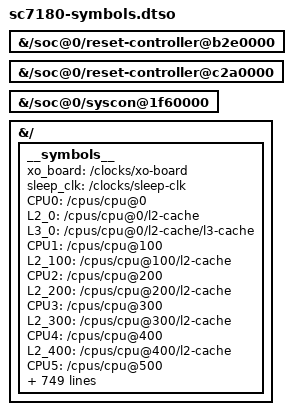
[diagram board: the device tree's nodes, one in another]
// SPDX-License-Identifier: BSD-3-Clause

/dts-v1/;
/plugin/;

/* need to insert a fun phandle to these since base dt doesn't have it... */
&{/soc@0/reset-controller@b2e0000} { phandle = <0x1001>; };
&{/soc@0/reset-controller@c2a0000} { phandle = <0x1002>; };
&{/soc@0/syscon@1f60000} { phandle = <0x1003>; };

/*
 * This is a funny hack to allow phandles on top of a dtb without --symbols
 */
&{/} {
	__symbols__ {
		xo_board = "/clocks/xo-board";
		sleep_clk = "/clocks/sleep-clk";
		CPU0 = "/cpus/cpu@0";
		L2_0 = "/cpus/cpu@0/l2-cache";
		L3_0 = "/cpus/cpu@0/l2-cache/l3-cache";
		CPU1 = "/cpus/cpu@100";
		L2_100 = "/cpus/cpu@100/l2-cache";
		CPU2 = "/cpus/cpu@200";
		L2_200 = "/cpus/cpu@200/l2-cache";
		CPU3 = "/cpus/cpu@300";
		L2_300 = "/cpus/cpu@300/l2-cache";
		CPU4 = "/cpus/cpu@400";
		L2_400 = "/cpus/cpu@400/l2-cache";
		CPU5 = "/cpus/cpu@500";
		L2_500 = "/cpus/cpu@500/l2-cache";
		CPU6 = "/cpus/cpu@600";
		L2_600 = "/cpus/cpu@600/l2-cache";
		CPU7 = "/cpus/cpu@700";
		L2_700 = "/cpus/cpu@700/l2-cache";
		idle_states = "/cpus/idle-states";
		LITTLE_CPU_SLEEP_0 = "/cpus/idle-states/cpu-sleep-0-0";
		LITTLE_CPU_SLEEP_1 = "/cpus/idle-states/cpu-sleep-0-1";
		BIG_CPU_SLEEP_0 = "/cpus/idle-states/cpu-sleep-1-0";
		BIG_CPU_SLEEP_1 = "/cpus/idle-states/cpu-sleep-1-1";
		CLUSTER_SLEEP_0 = "/cpus/idle-states/cluster-sleep-0";
		scm = "/firmware/scm";
		cpu0_opp_table = "/opp-table-cpu0";
		cpu0_opp1 = "/opp-table-cpu0/opp-300000000";
		cpu0_opp2 = "/opp-table-cpu0/opp-576000000";
		cpu0_opp3 = "/opp-table-cpu0/opp-768000000";
		cpu0_opp4 = "/opp-table-cpu0/opp-1017600000";
		cpu0_opp5 = "/opp-table-cpu0/opp-1248000000";
		cpu0_opp6 = "/opp-table-cpu0/opp-1324800000";
		cpu0_opp7 = "/opp-table-cpu0/opp-1516800000";
		cpu0_opp8 = "/opp-table-cpu0/opp-1612800000";
		cpu0_opp9 = "/opp-table-cpu0/opp-1708800000";
		cpu0_opp10 = "/opp-table-cpu0/opp-1804800000";
		cpu6_opp_table = "/opp-table-cpu6";
		cpu6_opp1 = "/opp-table-cpu6/opp-300000000";
		cpu6_opp2 = "/opp-table-cpu6/opp-652800000";
		cpu6_opp3 = "/opp-table-cpu6/opp-825600000";
		cpu6_opp4 = "/opp-table-cpu6/opp-979200000";
		cpu6_opp5 = "/opp-table-cpu6/opp-1113600000";
		cpu6_opp6 = "/opp-table-cpu6/opp-1267200000";
		cpu6_opp7 = "/opp-table-cpu6/opp-1555200000";
		cpu6_opp8 = "/opp-table-cpu6/opp-1708800000";
		cpu6_opp9 = "/opp-table-cpu6/opp-1843200000";
		cpu6_opp10 = "/opp-table-cpu6/opp-1900800000";
		cpu6_opp11 = "/opp-table-cpu6/opp-1996800000";
		cpu6_opp12 = "/opp-table-cpu6/opp-2112000000";
		cpu6_opp13 = "/opp-table-cpu6/opp-2208000000";
		cpu6_opp14 = "/opp-table-cpu6/opp-2323200000";
		cpu6_opp15 = "/opp-table-cpu6/opp-2400000000";
		cpu6_opp16 = "/opp-table-cpu6/opp-2553600000";
		qspi_opp_table = "/opp-table-qspi";
		qup_opp_table = "/opp-table-qup";
		reserved_memory = "/reserved-memory";
		aop_cmd_db_mem = "/reserved-memory/memory@80820000";
		smem_mem = "/reserved-memory/memory@80900000";
		atf_mem = "/reserved-memory/memory@80b00000";
		ipa_fw_mem = "/reserved-memory/memory@8b700000";
		rmtfs_mem = "/reserved-memory/memory@94600000";
		mpss_mem = "/reserved-memory/memory@86000000";
		camera_mem = "/reserved-memory/memory@8ec00000";
		venus_mem = "/reserved-memory/memory@8f600000";
		wlan_mem = "/reserved-memory/memory@94100000";
		mba_mem = "/reserved-memory/memory@94400000";
		mdata_mem = "/reserved-memory/mpss-metadata";
		cdsp_smp2p_out = "/smp2p-cdsp/master-kernel";
		cdsp_smp2p_in = "/smp2p-cdsp/slave-kernel";
		adsp_smp2p_out = "/smp2p-lpass/master-kernel";
		adsp_smp2p_in = "/smp2p-lpass/slave-kernel";
		modem_smp2p_out = "/smp2p-mpss/master-kernel";
		modem_smp2p_in = "/smp2p-mpss/slave-kernel";
		ipa_smp2p_out = "/smp2p-mpss/ipa-ap-to-modem";
		ipa_smp2p_in = "/smp2p-mpss/ipa-modem-to-ap";
		soc = "/soc@0";
		gcc = "/soc@0/clock-controller@100000";
		qfprom = "/soc@0/efuse@784000";
		qusb2p_hstx_trim = "/soc@0/efuse@784000/hstx-trim-primary@25b";
		gpu_speed_bin = "/soc@0/efuse@784000/gpu_speed_bin@1d2";
		sdhc_1 = "/soc@0/mmc@7c4000";
		sdhc1_opp_table = "/soc@0/mmc@7c4000/opp-table";
		qupv3_id_0 = "/soc@0/geniqup@8c0000";
		i2c0 = "/soc@0/geniqup@8c0000/i2c@880000";
		spi0 = "/soc@0/geniqup@8c0000/spi@880000";
		uart0 = "/soc@0/geniqup@8c0000/serial@880000";
		i2c1 = "/soc@0/geniqup@8c0000/i2c@884000";
		spi1 = "/soc@0/geniqup@8c0000/spi@884000";
		uart1 = "/soc@0/geniqup@8c0000/serial@884000";
		i2c2 = "/soc@0/geniqup@8c0000/i2c@888000";
		uart2 = "/soc@0/geniqup@8c0000/serial@888000";
		i2c3 = "/soc@0/geniqup@8c0000/i2c@88c000";
		spi3 = "/soc@0/geniqup@8c0000/spi@88c000";
		uart3 = "/soc@0/geniqup@8c0000/serial@88c000";
		bluetooth = "/soc@0/geniqup@8c0000/serial@88c000/bluetooth";
		i2c4 = "/soc@0/geniqup@8c0000/i2c@890000";
		uart4 = "/soc@0/geniqup@8c0000/serial@890000";
		i2c5 = "/soc@0/geniqup@8c0000/i2c@894000";
		spi5 = "/soc@0/geniqup@8c0000/spi@894000";
		uart5 = "/soc@0/geniqup@8c0000/serial@894000";
		qupv3_id_1 = "/soc@0/geniqup@ac0000";
		i2c6 = "/soc@0/geniqup@ac0000/i2c@a80000";
		spi6 = "/soc@0/geniqup@ac0000/spi@a80000";
		uart6 = "/soc@0/geniqup@ac0000/serial@a80000";
		i2c7 = "/soc@0/geniqup@ac0000/i2c@a84000";
		uart7 = "/soc@0/geniqup@ac0000/serial@a84000";
		i2c8 = "/soc@0/geniqup@ac0000/i2c@a88000";
		spi8 = "/soc@0/geniqup@ac0000/spi@a88000";
		uart8 = "/soc@0/geniqup@ac0000/serial@a88000";
		i2c9 = "/soc@0/geniqup@ac0000/i2c@a8c000";
		uart9 = "/soc@0/geniqup@ac0000/serial@a8c000";
		i2c10 = "/soc@0/geniqup@ac0000/i2c@a90000";
		spi10 = "/soc@0/geniqup@ac0000/spi@a90000";
		uart10 = "/soc@0/geniqup@ac0000/serial@a90000";
		i2c11 = "/soc@0/geniqup@ac0000/i2c@a94000";
		spi11 = "/soc@0/geniqup@ac0000/spi@a94000";
		uart11 = "/soc@0/geniqup@ac0000/serial@a94000";
		config_noc = "/soc@0/interconnect@1500000";
		system_noc = "/soc@0/interconnect@1620000";
		mc_virt = "/soc@0/interconnect@1638000";
		qup_virt = "/soc@0/interconnect@1650000";
		aggre1_noc = "/soc@0/interconnect@16e0000";
		aggre2_noc = "/soc@0/interconnect@1705000";
		compute_noc = "/soc@0/interconnect@170e000";
		mmss_noc = "/soc@0/interconnect@1740000";
		ipa = "/soc@0/ipa@1e40000";
		tcsr_mutex = "/soc@0/hwlock@1f40000";
		tcsr_regs_1 = "/soc@0/syscon@1f60000";
		tcsr_regs_2 = "/soc@0/syscon@1fc0000";
		tlmm = "/soc@0/pinctrl@3500000";
		dp_hot_plug_det = "/soc@0/pinctrl@3500000/dp-hot-plug-det-state";
		qspi_clk = "/soc@0/pinctrl@3500000/qspi-clk-state";
		qspi_cs0 = "/soc@0/pinctrl@3500000/qspi-cs0-state";
		qspi_cs1 = "/soc@0/pinctrl@3500000/qspi-cs1-state";
		qspi_data0 = "/soc@0/pinctrl@3500000/qspi-data0-state";
		qspi_data1 = "/soc@0/pinctrl@3500000/qspi-data1-state";
		qspi_data23 = "/soc@0/pinctrl@3500000/qspi-data23-state";
		qup_i2c0_default = "/soc@0/pinctrl@3500000/qup-i2c0-default-state";
		qup_i2c1_default = "/soc@0/pinctrl@3500000/qup-i2c1-default-state";
		qup_i2c2_default = "/soc@0/pinctrl@3500000/qup-i2c2-default-state";
		qup_i2c3_default = "/soc@0/pinctrl@3500000/qup-i2c3-default-state";
		qup_i2c4_default = "/soc@0/pinctrl@3500000/qup-i2c4-default-state";
		qup_i2c5_default = "/soc@0/pinctrl@3500000/qup-i2c5-default-state";
		qup_i2c6_default = "/soc@0/pinctrl@3500000/qup-i2c6-default-state";
		qup_i2c7_default = "/soc@0/pinctrl@3500000/qup-i2c7-default-state";
		qup_i2c8_default = "/soc@0/pinctrl@3500000/qup-i2c8-default-state";
		qup_i2c9_default = "/soc@0/pinctrl@3500000/qup-i2c9-default-state";
		qup_i2c10_default = "/soc@0/pinctrl@3500000/qup-i2c10-default-state";
		qup_i2c11_default = "/soc@0/pinctrl@3500000/qup-i2c11-default-state";
		qup_spi0_spi = "/soc@0/pinctrl@3500000/qup-spi0-spi-state";
		qup_spi0_cs = "/soc@0/pinctrl@3500000/qup-spi0-cs-state";
		qup_spi0_cs_gpio = "/soc@0/pinctrl@3500000/qup-spi0-cs-gpio-state";
		qup_spi1_spi = "/soc@0/pinctrl@3500000/qup-spi1-spi-state";
		qup_spi1_cs = "/soc@0/pinctrl@3500000/qup-spi1-cs-state";
		qup_spi1_cs_gpio = "/soc@0/pinctrl@3500000/qup-spi1-cs-gpio-state";
		qup_spi3_spi = "/soc@0/pinctrl@3500000/qup-spi3-spi-state";
		qup_spi3_cs = "/soc@0/pinctrl@3500000/qup-spi3-cs-state";
		qup_spi3_cs_gpio = "/soc@0/pinctrl@3500000/qup-spi3-cs-gpio-state";
		qup_spi5_spi = "/soc@0/pinctrl@3500000/qup-spi5-spi-state";
		qup_spi5_cs = "/soc@0/pinctrl@3500000/qup-spi5-cs-state";
		qup_spi5_cs_gpio = "/soc@0/pinctrl@3500000/qup-spi5-cs-gpio-state";
		qup_spi6_spi = "/soc@0/pinctrl@3500000/qup-spi6-spi-state";
		qup_spi6_cs = "/soc@0/pinctrl@3500000/qup-spi6-cs-state";
		qup_spi6_cs_gpio = "/soc@0/pinctrl@3500000/qup-spi6-cs-gpio-state";
		qup_spi8_spi = "/soc@0/pinctrl@3500000/qup-spi8-spi-state";
		qup_spi8_cs = "/soc@0/pinctrl@3500000/qup-spi8-cs-state";
		qup_spi8_cs_gpio = "/soc@0/pinctrl@3500000/qup-spi8-cs-gpio-state";
		qup_spi10_spi = "/soc@0/pinctrl@3500000/qup-spi10-spi-state";
		qup_spi10_cs = "/soc@0/pinctrl@3500000/qup-spi10-cs-state";
		qup_spi10_cs_gpio = "/soc@0/pinctrl@3500000/qup-spi10-cs-gpio-state";
		qup_spi11_spi = "/soc@0/pinctrl@3500000/qup-spi11-spi-state";
		qup_spi11_cs = "/soc@0/pinctrl@3500000/qup-spi11-cs-state";
		qup_spi11_cs_gpio = "/soc@0/pinctrl@3500000/qup-spi11-cs-gpio-state";
		qup_uart0_default = "/soc@0/pinctrl@3500000/qup-uart0-default-state";
		qup_uart0_cts = "/soc@0/pinctrl@3500000/qup-uart0-default-state/cts-pins";
		qup_uart0_rts = "/soc@0/pinctrl@3500000/qup-uart0-default-state/rts-pins";
		qup_uart0_tx = "/soc@0/pinctrl@3500000/qup-uart0-default-state/tx-pins";
		qup_uart0_rx = "/soc@0/pinctrl@3500000/qup-uart0-default-state/rx-pins";
		qup_uart1_default = "/soc@0/pinctrl@3500000/qup-uart1-default-state";
		qup_uart1_cts = "/soc@0/pinctrl@3500000/qup-uart1-default-state/cts-pins";
		qup_uart1_rts = "/soc@0/pinctrl@3500000/qup-uart1-default-state/rts-pins";
		qup_uart1_tx = "/soc@0/pinctrl@3500000/qup-uart1-default-state/tx-pins";
		qup_uart1_rx = "/soc@0/pinctrl@3500000/qup-uart1-default-state/rx-pins";
		qup_uart2_default = "/soc@0/pinctrl@3500000/qup-uart2-default-state";
		qup_uart2_tx = "/soc@0/pinctrl@3500000/qup-uart2-default-state/tx-pins";
		qup_uart2_rx = "/soc@0/pinctrl@3500000/qup-uart2-default-state/rx-pins";
		qup_uart3_default = "/soc@0/pinctrl@3500000/qup-uart3-default-state";
		qup_uart3_cts = "/soc@0/pinctrl@3500000/qup-uart3-default-state/cts-pins";
		qup_uart3_rts = "/soc@0/pinctrl@3500000/qup-uart3-default-state/rts-pins";
		qup_uart3_tx = "/soc@0/pinctrl@3500000/qup-uart3-default-state/tx-pins";
		qup_uart3_rx = "/soc@0/pinctrl@3500000/qup-uart3-default-state/rx-pins";
		qup_uart4_default = "/soc@0/pinctrl@3500000/qup-uart4-default-state";
		qup_uart4_tx = "/soc@0/pinctrl@3500000/qup-uart4-default-state/tx-pins";
		qup_uart4_rx = "/soc@0/pinctrl@3500000/qup-uart4-default-state/rx-pins";
		qup_uart5_default = "/soc@0/pinctrl@3500000/qup-uart5-default-state";
		qup_uart5_cts = "/soc@0/pinctrl@3500000/qup-uart5-default-state/cts-pins";
		qup_uart5_rts = "/soc@0/pinctrl@3500000/qup-uart5-default-state/rts-pins";
		qup_uart5_tx = "/soc@0/pinctrl@3500000/qup-uart5-default-state/tx-pins";
		qup_uart5_rx = "/soc@0/pinctrl@3500000/qup-uart5-default-state/rx-pins";
		qup_uart6_default = "/soc@0/pinctrl@3500000/qup-uart6-default-state";
		qup_uart6_cts = "/soc@0/pinctrl@3500000/qup-uart6-default-state/cts-pins";
		qup_uart6_rts = "/soc@0/pinctrl@3500000/qup-uart6-default-state/rts-pins";
		qup_uart6_tx = "/soc@0/pinctrl@3500000/qup-uart6-default-state/tx-pins";
		qup_uart6_rx = "/soc@0/pinctrl@3500000/qup-uart6-default-state/rx-pins";
		qup_uart7_default = "/soc@0/pinctrl@3500000/qup-uart7-default-state";
		qup_uart7_tx = "/soc@0/pinctrl@3500000/qup-uart7-default-state/tx-pins";
		qup_uart7_rx = "/soc@0/pinctrl@3500000/qup-uart7-default-state/rx-pins";
		qup_uart8_default = "/soc@0/pinctrl@3500000/qup-uart8-default-state";
		qup_uart8_tx = "/soc@0/pinctrl@3500000/qup-uart8-default-state/tx-pins";
		qup_uart8_rx = "/soc@0/pinctrl@3500000/qup-uart8-default-state/rx-pins";
		qup_uart9_default = "/soc@0/pinctrl@3500000/qup-uart9-default-state";
		qup_uart9_tx = "/soc@0/pinctrl@3500000/qup-uart9-default-state/tx-pins";
		qup_uart9_rx = "/soc@0/pinctrl@3500000/qup-uart9-default-state/rx-pins";
		qup_uart10_default = "/soc@0/pinctrl@3500000/qup-uart10-default-state";
		qup_uart10_cts = "/soc@0/pinctrl@3500000/qup-uart10-default-state/cts-pins";
		qup_uart10_rts = "/soc@0/pinctrl@3500000/qup-uart10-default-state/rts-pins";
		qup_uart10_tx = "/soc@0/pinctrl@3500000/qup-uart10-default-state/tx-pins";
		qup_uart10_rx = "/soc@0/pinctrl@3500000/qup-uart10-default-state/rx-pins";
		qup_uart11_default = "/soc@0/pinctrl@3500000/qup-uart11-default-state";
		qup_uart11_cts = "/soc@0/pinctrl@3500000/qup-uart11-default-state/cts-pins";
		qup_uart11_rts = "/soc@0/pinctrl@3500000/qup-uart11-default-state/rts-pins";
		qup_uart11_tx = "/soc@0/pinctrl@3500000/qup-uart11-default-state/tx-pins";
		qup_uart11_rx = "/soc@0/pinctrl@3500000/qup-uart11-default-state/rx-pins";
		sec_mi2s_active = "/soc@0/pinctrl@3500000/sec-mi2s-active-state";
		pri_mi2s_active = "/soc@0/pinctrl@3500000/pri-mi2s-active-state";
		pri_mi2s_mclk_active = "/soc@0/pinctrl@3500000/pri-mi2s-mclk-active-state";
		ter_mi2s_active = "/soc@0/pinctrl@3500000/ter-mi2s-active-state";
		qup_uart3_sleep = "/soc@0/pinctrl@3500000/qup-uart3-sleep-state";
		sdc1_on = "/soc@0/pinctrl@3500000/sdc1-on-state";
		sdc1_off = "/soc@0/pinctrl@3500000/sdc1-off-state";
		sdc2_on = "/soc@0/pinctrl@3500000/sdc2-on-state";
		sdc2_off = "/soc@0/pinctrl@3500000/sdc2-off-state";
		remoteproc_mpss = "/soc@0/remoteproc@4080000";
		gpu = "/soc@0/gpu@5000000";
		gpu_opp_table = "/soc@0/gpu@5000000/opp-table";
		adreno_smmu = "/soc@0/iommu@5040000";
		gmu = "/soc@0/gmu@506a000";
		gmu_opp_table = "/soc@0/gmu@506a000/opp-table";
		gpucc = "/soc@0/clock-controller@5090000";
		stm_out = "/soc@0/stm@6002000/out-ports/port/endpoint";
		funnel0_out = "/soc@0/funnel@6041000/out-ports/port/endpoint";
		funnel0_in7 = "/soc@0/funnel@6041000/in-ports/port@7/endpoint";
		funnel1_out = "/soc@0/funnel@6042000/out-ports/port/endpoint";
		funnel1_in4 = "/soc@0/funnel@6042000/in-ports/port@4/endpoint";
		merge_funnel_out = "/soc@0/funnel@6045000/out-ports/port/endpoint";
		merge_funnel_in0 = "/soc@0/funnel@6045000/in-ports/port@0/endpoint";
		merge_funnel_in1 = "/soc@0/funnel@6045000/in-ports/port@1/endpoint";
		replicator_out = "/soc@0/replicator@6046000/out-ports/port/endpoint";
		replicator_in = "/soc@0/replicator@6046000/in-ports/port/endpoint";
		etr_in = "/soc@0/etr@6048000/in-ports/port/endpoint";
		swao_funnel_out = "/soc@0/funnel@6b04000/out-ports/port/endpoint";
		swao_funnel_in = "/soc@0/funnel@6b04000/in-ports/port@7/endpoint";
		etf_out = "/soc@0/etf@6b05000/out-ports/port/endpoint";
		etf_in = "/soc@0/etf@6b05000/in-ports/port/endpoint";
		swao_replicator_out = "/soc@0/replicator@6b06000/out-ports/port/endpoint";
		swao_replicator_in = "/soc@0/replicator@6b06000/in-ports/port/endpoint";
		etm0_out = "/soc@0/etm@7040000/out-ports/port/endpoint";
		etm1_out = "/soc@0/etm@7140000/out-ports/port/endpoint";
		etm2_out = "/soc@0/etm@7240000/out-ports/port/endpoint";
		etm3_out = "/soc@0/etm@7340000/out-ports/port/endpoint";
		etm4_out = "/soc@0/etm@7440000/out-ports/port/endpoint";
		etm5_out = "/soc@0/etm@7540000/out-ports/port/endpoint";
		etm6_out = "/soc@0/etm@7640000/out-ports/port/endpoint";
		etm7_out = "/soc@0/etm@7740000/out-ports/port/endpoint";
		apss_funnel_out = "/soc@0/funnel@7800000/out-ports/port/endpoint";
		apss_funnel_in0 = "/soc@0/funnel@7800000/in-ports/port@0/endpoint";
		apss_funnel_in1 = "/soc@0/funnel@7800000/in-ports/port@1/endpoint";
		apss_funnel_in2 = "/soc@0/funnel@7800000/in-ports/port@2/endpoint";
		apss_funnel_in3 = "/soc@0/funnel@7800000/in-ports/port@3/endpoint";
		apss_funnel_in4 = "/soc@0/funnel@7800000/in-ports/port@4/endpoint";
		apss_funnel_in5 = "/soc@0/funnel@7800000/in-ports/port@5/endpoint";
		apss_funnel_in6 = "/soc@0/funnel@7800000/in-ports/port@6/endpoint";
		apss_funnel_in7 = "/soc@0/funnel@7800000/in-ports/port@7/endpoint";
		apss_merge_funnel_out = "/soc@0/funnel@7810000/out-ports/port/endpoint";
		apss_merge_funnel_in = "/soc@0/funnel@7810000/in-ports/port/endpoint";
		sdhc_2 = "/soc@0/mmc@8804000";
		sdhc2_opp_table = "/soc@0/mmc@8804000/opp-table";
		qspi = "/soc@0/spi@88dc000";
		usb_1_hsphy = "/soc@0/phy@88e3000";
		usb_1_qmpphy = "/soc@0/phy@88e8000";
		cpu_bwmon_opp_table = "/soc@0/pmu@90b6300/opp-table";
		llcc_bwmon_opp_table = "/soc@0/pmu@90cd000/opp-table";
		dc_noc = "/soc@0/interconnect@9160000";
		gem_noc = "/soc@0/interconnect@9680000";
		npu_noc = "/soc@0/interconnect@9990000";
		usb_1 = "/soc@0/usb@a6f8800";
		usb_1_dwc3 = "/soc@0/usb@a6f8800/usb@a600000";
		venus = "/soc@0/video-codec@aa00000";
		venus_opp_table = "/soc@0/video-codec@aa00000/opp-table";
		videocc = "/soc@0/clock-controller@ab00000";
		camnoc_virt = "/soc@0/interconnect@ac00000";
		camcc = "/soc@0/clock-controller@ad00000";
		mdss = "/soc@0/display-subsystem@ae00000";
		mdp = "/soc@0/display-subsystem@ae00000/display-controller@ae01000";
		dpu_intf1_out = "/soc@0/display-subsystem@ae00000/display-controller@ae01000/ports/port@0/endpoint";
		dpu_intf0_out = "/soc@0/display-subsystem@ae00000/display-controller@ae01000/ports/port@2/endpoint";
		mdp_opp_table = "/soc@0/display-subsystem@ae00000/display-controller@ae01000/opp-table";
		mdss_dsi0 = "/soc@0/display-subsystem@ae00000/dsi@ae94000";
		mdss_dsi0_in = "/soc@0/display-subsystem@ae00000/dsi@ae94000/ports/port@0/endpoint";
		mdss_dsi0_out = "/soc@0/display-subsystem@ae00000/dsi@ae94000/ports/port@1/endpoint";
		dsi_opp_table = "/soc@0/display-subsystem@ae00000/dsi@ae94000/opp-table";
		panel0_in = "/soc@0/display-subsystem@ae00000/dsi@ae94000/panel@0/port/endpoint";
		mdss_dsi0_phy = "/soc@0/display-subsystem@ae00000/phy@ae94400";
		mdss_dp = "/soc@0/display-subsystem@ae00000/displayport-controller@ae90000";
		dp_in = "/soc@0/display-subsystem@ae00000/displayport-controller@ae90000/ports/port@0/endpoint";
		mdss_dp_out = "/soc@0/display-subsystem@ae00000/displayport-controller@ae90000/ports/port@1/endpoint";
		dp_opp_table = "/soc@0/display-subsystem@ae00000/displayport-controller@ae90000/opp-table";
		dispcc = "/soc@0/clock-controller@af00000";
		pdc = "/soc@0/interrupt-controller@b220000";
		pdc_reset = "/soc@0/reset-controller@b2e0000";
		tsens0 = "/soc@0/thermal-sensor@c263000";
		tsens1 = "/soc@0/thermal-sensor@c265000";
		aoss_reset = "/soc@0/reset-controller@c2a0000";
		aoss_qmp = "/soc@0/power-management@c300000";
		spmi_bus = "/soc@0/spmi@c440000";
		pm6150_lsid0 = "/soc@0/spmi@c440000/pmic@0";
		pm6150_pon = "/soc@0/spmi@c440000/pmic@0/pon@800";
		pm6150_pwrkey = "/soc@0/spmi@c440000/pmic@0/pon@800/pwrkey";
		pm6150_resin = "/soc@0/spmi@c440000/pmic@0/pon@800/resin";
		pm6150_temp = "/soc@0/spmi@c440000/pmic@0/temp-alarm@2400";
		pm6150_adc = "/soc@0/spmi@c440000/pmic@0/adc@3100";
		pm6150_adc_tm = "/soc@0/spmi@c440000/pmic@0/adc-tm@3500";
		pm6150_rtc = "/soc@0/spmi@c440000/pmic@0/rtc@6000";
		pm6150_gpios = "/soc@0/spmi@c440000/pmic@0/gpio@c000";
		pm6150_lsid1 = "/soc@0/spmi@c440000/pmic@1";
		pm6150l_lsid4 = "/soc@0/spmi@c440000/pmic@4";
		pm6150l_temp = "/soc@0/spmi@c440000/pmic@4/temp-alarm@2400";
		pm6150l_adc = "/soc@0/spmi@c440000/pmic@4/adc@3100";
		pm6150l_adc_tm = "/soc@0/spmi@c440000/pmic@4/adc-tm@3500";
		pm6150l_gpios = "/soc@0/spmi@c440000/pmic@4/gpio@c000";
		disp_pins = "/soc@0/spmi@c440000/pmic@4/gpio@c000/disp-state";
		pm6150l_lsid5 = "/soc@0/spmi@c440000/pmic@5";
		pm6150l_flash = "/soc@0/spmi@c440000/pmic@5/led-controller@d300";
		pm6150l_wled = "/soc@0/spmi@c440000/pmic@5/leds@d800";
		apps_smmu = "/soc@0/iommu@15000000";
		intc = "/soc@0/interrupt-controller@17a00000";
		apss_shared = "/soc@0/mailbox@17c00000";
		apps_rsc = "/soc@0/rsc@18200000";
		rpmhcc = "/soc@0/rsc@18200000/clock-controller";
		rpmhpd = "/soc@0/rsc@18200000/power-controller";
		rpmhpd_opp_table = "/soc@0/rsc@18200000/power-controller/opp-table";
		rpmhpd_opp_ret = "/soc@0/rsc@18200000/power-controller/opp-table/opp1";
		rpmhpd_opp_min_svs = "/soc@0/rsc@18200000/power-controller/opp-table/opp2";
		rpmhpd_opp_low_svs = "/soc@0/rsc@18200000/power-controller/opp-table/opp3";
		rpmhpd_opp_svs = "/soc@0/rsc@18200000/power-controller/opp-table/opp4";
		rpmhpd_opp_svs_l1 = "/soc@0/rsc@18200000/power-controller/opp-table/opp5";
		rpmhpd_opp_svs_l2 = "/soc@0/rsc@18200000/power-controller/opp-table/opp6";
		rpmhpd_opp_nom = "/soc@0/rsc@18200000/power-controller/opp-table/opp7";
		rpmhpd_opp_nom_l1 = "/soc@0/rsc@18200000/power-controller/opp-table/opp8";
		rpmhpd_opp_nom_l2 = "/soc@0/rsc@18200000/power-controller/opp-table/opp9";
		rpmhpd_opp_turbo = "/soc@0/rsc@18200000/power-controller/opp-table/opp10";
		rpmhpd_opp_turbo_l1 = "/soc@0/rsc@18200000/power-controller/opp-table/opp11";
		apps_bcm_voter = "/soc@0/rsc@18200000/bcm-voter";
		vreg_s1a_1p1 = "/soc@0/rsc@18200000/regulators-0/smps1";
		vreg_s4a_1p0 = "/soc@0/rsc@18200000/regulators-0/smps4";
		vreg_s5a_2p0 = "/soc@0/rsc@18200000/regulators-0/smps5";
		vreg_l1a_1p2 = "/soc@0/rsc@18200000/regulators-0/ldo1";
		vreg_l2a_1p0 = "/soc@0/rsc@18200000/regulators-0/ldo2";
		vreg_l3a_1p0 = "/soc@0/rsc@18200000/regulators-0/ldo3";
		vreg_l4a_0p8 = "/soc@0/rsc@18200000/regulators-0/ldo4";
		vreg_l5a_2p7 = "/soc@0/rsc@18200000/regulators-0/ldo5";
		vreg_l6a_0p6 = "/soc@0/rsc@18200000/regulators-0/ldo6";
		vreg_l9a_0p6 = "/soc@0/rsc@18200000/regulators-0/ldo9";
		vreg_l10a_1p8 = "/soc@0/rsc@18200000/regulators-0/ldo10";
		vreg_l11a_1p8 = "/soc@0/rsc@18200000/regulators-0/ldo11";
		vreg_l12a_1p8 = "/soc@0/rsc@18200000/regulators-0/ldo12";
		vreg_l13a_1p8 = "/soc@0/rsc@18200000/regulators-0/ldo13";
		vreg_l14a_1p8 = "/soc@0/rsc@18200000/regulators-0/ldo14";
		vreg_l15a_1p8 = "/soc@0/rsc@18200000/regulators-0/ldo15";
		vreg_l16a_2p7 = "/soc@0/rsc@18200000/regulators-0/ldo16";
		vreg_l17a_3p0 = "/soc@0/rsc@18200000/regulators-0/ldo17";
		vreg_l18a_2p8 = "/soc@0/rsc@18200000/regulators-0/ldo18";
		vreg_l19a_2p9 = "/soc@0/rsc@18200000/regulators-0/ldo19";
		vreg_s8c_1p3 = "/soc@0/rsc@18200000/regulators-1/smps8";
		vreg_l1c_1p8 = "/soc@0/rsc@18200000/regulators-1/ldo1";
		vreg_l2c_1p3 = "/soc@0/rsc@18200000/regulators-1/ldo2";
		vreg_l3c_1p2 = "/soc@0/rsc@18200000/regulators-1/ldo3";
		vreg_l4c_1p8 = "/soc@0/rsc@18200000/regulators-1/ldo4";
		vreg_l5c_1p8 = "/soc@0/rsc@18200000/regulators-1/ldo5";
		vreg_l6c_2p9 = "/soc@0/rsc@18200000/regulators-1/ldo6";
		vreg_l7c_3p0 = "/soc@0/rsc@18200000/regulators-1/ldo7";
		vreg_l8c_1p8 = "/soc@0/rsc@18200000/regulators-1/ldo8";
		vreg_l9c_2p9 = "/soc@0/rsc@18200000/regulators-1/ldo9";
		vreg_l10c_3p3 = "/soc@0/rsc@18200000/regulators-1/ldo10";
		vreg_l11c_3p3 = "/soc@0/rsc@18200000/regulators-1/ldo11";
		vreg_bob = "/soc@0/rsc@18200000/regulators-1/bob";
		osm_l3 = "/soc@0/interconnect@18321000";
		cpufreq_hw = "/soc@0/cpufreq@18323000";
		wifi = "/soc@0/wifi@18800000";
		remoteproc_adsp = "/soc@0/remoteproc@62400000";
		q6afe = "/soc@0/remoteproc@62400000/glink-edge/apr/service@4";
		q6afedai = "/soc@0/remoteproc@62400000/glink-edge/apr/service@4/dais";
		q6afecc = "/soc@0/remoteproc@62400000/glink-edge/apr/service@4/clock-controller";
		q6asm = "/soc@0/remoteproc@62400000/glink-edge/apr/service@7";
		q6asmdai = "/soc@0/remoteproc@62400000/glink-edge/apr/service@7/dais";
		q6adm = "/soc@0/remoteproc@62400000/glink-edge/apr/service@8";
		q6routing = "/soc@0/remoteproc@62400000/glink-edge/apr/service@8/routing";
		lpasscc = "/soc@0/clock-controller@62d00000";
		lpass_cpu = "/soc@0/lpass@62d87000";
		lpass_hm = "/soc@0/clock-controller@63000000";
		cpu0_thermal = "/thermal-zones/cpu0-thermal";
		cpu0_alert0 = "/thermal-zones/cpu0-thermal/trips/trip-point0";
		cpu0_alert1 = "/thermal-zones/cpu0-thermal/trips/trip-point1";
		cpu0_crit = "/thermal-zones/cpu0-thermal/trips/cpu-crit";
		cpu1_thermal = "/thermal-zones/cpu1-thermal";
		cpu1_alert0 = "/thermal-zones/cpu1-thermal/trips/trip-point0";
		cpu1_alert1 = "/thermal-zones/cpu1-thermal/trips/trip-point1";
		cpu1_crit = "/thermal-zones/cpu1-thermal/trips/cpu-crit";
		cpu2_thermal = "/thermal-zones/cpu2-thermal";
		cpu2_alert0 = "/thermal-zones/cpu2-thermal/trips/trip-point0";
		cpu2_alert1 = "/thermal-zones/cpu2-thermal/trips/trip-point1";
		cpu2_crit = "/thermal-zones/cpu2-thermal/trips/cpu-crit";
		cpu3_thermal = "/thermal-zones/cpu3-thermal";
		cpu3_alert0 = "/thermal-zones/cpu3-thermal/trips/trip-point0";
		cpu3_alert1 = "/thermal-zones/cpu3-thermal/trips/trip-point1";
		cpu3_crit = "/thermal-zones/cpu3-thermal/trips/cpu-crit";
		cpu4_thermal = "/thermal-zones/cpu4-thermal";
		cpu4_alert0 = "/thermal-zones/cpu4-thermal/trips/trip-point0";
		cpu4_alert1 = "/thermal-zones/cpu4-thermal/trips/trip-point1";
		cpu4_crit = "/thermal-zones/cpu4-thermal/trips/cpu-crit";
		cpu5_thermal = "/thermal-zones/cpu5-thermal";
		cpu5_alert0 = "/thermal-zones/cpu5-thermal/trips/trip-point0";
		cpu5_alert1 = "/thermal-zones/cpu5-thermal/trips/trip-point1";
		cpu5_crit = "/thermal-zones/cpu5-thermal/trips/cpu-crit";
		cpu6_thermal = "/thermal-zones/cpu6-thermal";
		cpu6_alert0 = "/thermal-zones/cpu6-thermal/trips/trip-point0";
		cpu6_alert1 = "/thermal-zones/cpu6-thermal/trips/trip-point1";
		cpu6_crit = "/thermal-zones/cpu6-thermal/trips/cpu-crit";
		cpu7_thermal = "/thermal-zones/cpu7-thermal";
		cpu7_alert0 = "/thermal-zones/cpu7-thermal/trips/trip-point0";
		cpu7_alert1 = "/thermal-zones/cpu7-thermal/trips/trip-point1";
		cpu7_crit = "/thermal-zones/cpu7-thermal/trips/cpu-crit";
		cpu8_thermal = "/thermal-zones/cpu8-thermal";
		cpu8_alert0 = "/thermal-zones/cpu8-thermal/trips/trip-point0";
		cpu8_alert1 = "/thermal-zones/cpu8-thermal/trips/trip-point1";
		cpu8_crit = "/thermal-zones/cpu8-thermal/trips/cpu-crit";
		cpu9_thermal = "/thermal-zones/cpu9-thermal";
		cpu9_alert0 = "/thermal-zones/cpu9-thermal/trips/trip-point0";
		cpu9_alert1 = "/thermal-zones/cpu9-thermal/trips/trip-point1";
		cpu9_crit = "/thermal-zones/cpu9-thermal/trips/cpu-crit";
		aoss0_alert0 = "/thermal-zones/aoss0-thermal/trips/trip-point0";
		aoss0_crit = "/thermal-zones/aoss0-thermal/trips/aoss0-crit";
		cpuss0_alert0 = "/thermal-zones/cpuss0-thermal/trips/trip-point0";
		cpuss0_crit = "/thermal-zones/cpuss0-thermal/trips/cluster0-crit";
		cpuss1_alert0 = "/thermal-zones/cpuss1-thermal/trips/trip-point0";
		cpuss1_crit = "/thermal-zones/cpuss1-thermal/trips/cluster0-crit";
		gpuss0_alert0 = "/thermal-zones/gpuss0-thermal/trips/trip-point0";
		gpuss0_crit = "/thermal-zones/gpuss0-thermal/trips/gpuss0-crit";
		gpuss1_alert0 = "/thermal-zones/gpuss1-thermal/trips/trip-point0";
		gpuss1_crit = "/thermal-zones/gpuss1-thermal/trips/gpuss1-crit";
		aoss1_alert0 = "/thermal-zones/aoss1-thermal/trips/trip-point0";
		aoss1_crit = "/thermal-zones/aoss1-thermal/trips/aoss1-crit";
		cwlan_alert0 = "/thermal-zones/cwlan-thermal/trips/trip-point0";
		cwlan_crit = "/thermal-zones/cwlan-thermal/trips/cwlan-crit";
		audio_alert0 = "/thermal-zones/audio-thermal/trips/trip-point0";
		audio_crit = "/thermal-zones/audio-thermal/trips/audio-crit";
		ddr_alert0 = "/thermal-zones/ddr-thermal/trips/trip-point0";
		ddr_crit = "/thermal-zones/ddr-thermal/trips/ddr-crit";
		q6_hvx_alert0 = "/thermal-zones/q6-hvx-thermal/trips/trip-point0";
		q6_hvx_crit = "/thermal-zones/q6-hvx-thermal/trips/q6-hvx-crit";
		camera_alert0 = "/thermal-zones/camera-thermal/trips/trip-point0";
		camera_crit = "/thermal-zones/camera-thermal/trips/camera-crit";
		mdm_alert0 = "/thermal-zones/mdm-core-thermal/trips/trip-point0";
		mdm_crit = "/thermal-zones/mdm-core-thermal/trips/mdm-crit";
		mdm_dsp_alert0 = "/thermal-zones/mdm-dsp-thermal/trips/trip-point0";
		mdm_dsp_crit = "/thermal-zones/mdm-dsp-thermal/trips/mdm-dsp-crit";
		npu_alert0 = "/thermal-zones/npu-thermal/trips/trip-point0";
		npu_crit = "/thermal-zones/npu-thermal/trips/npu-crit";
		video_alert0 = "/thermal-zones/video-thermal/trips/trip-point0";
		video_crit = "/thermal-zones/video-thermal/trips/video-crit";
		pm6150_thermal = "/thermal-zones/pm6150-thermal";
		pm6150_trip0 = "/thermal-zones/pm6150-thermal/trips/trip0";
		pm6150_crit = "/thermal-zones/pm6150-thermal/trips/crit";
	};
};
